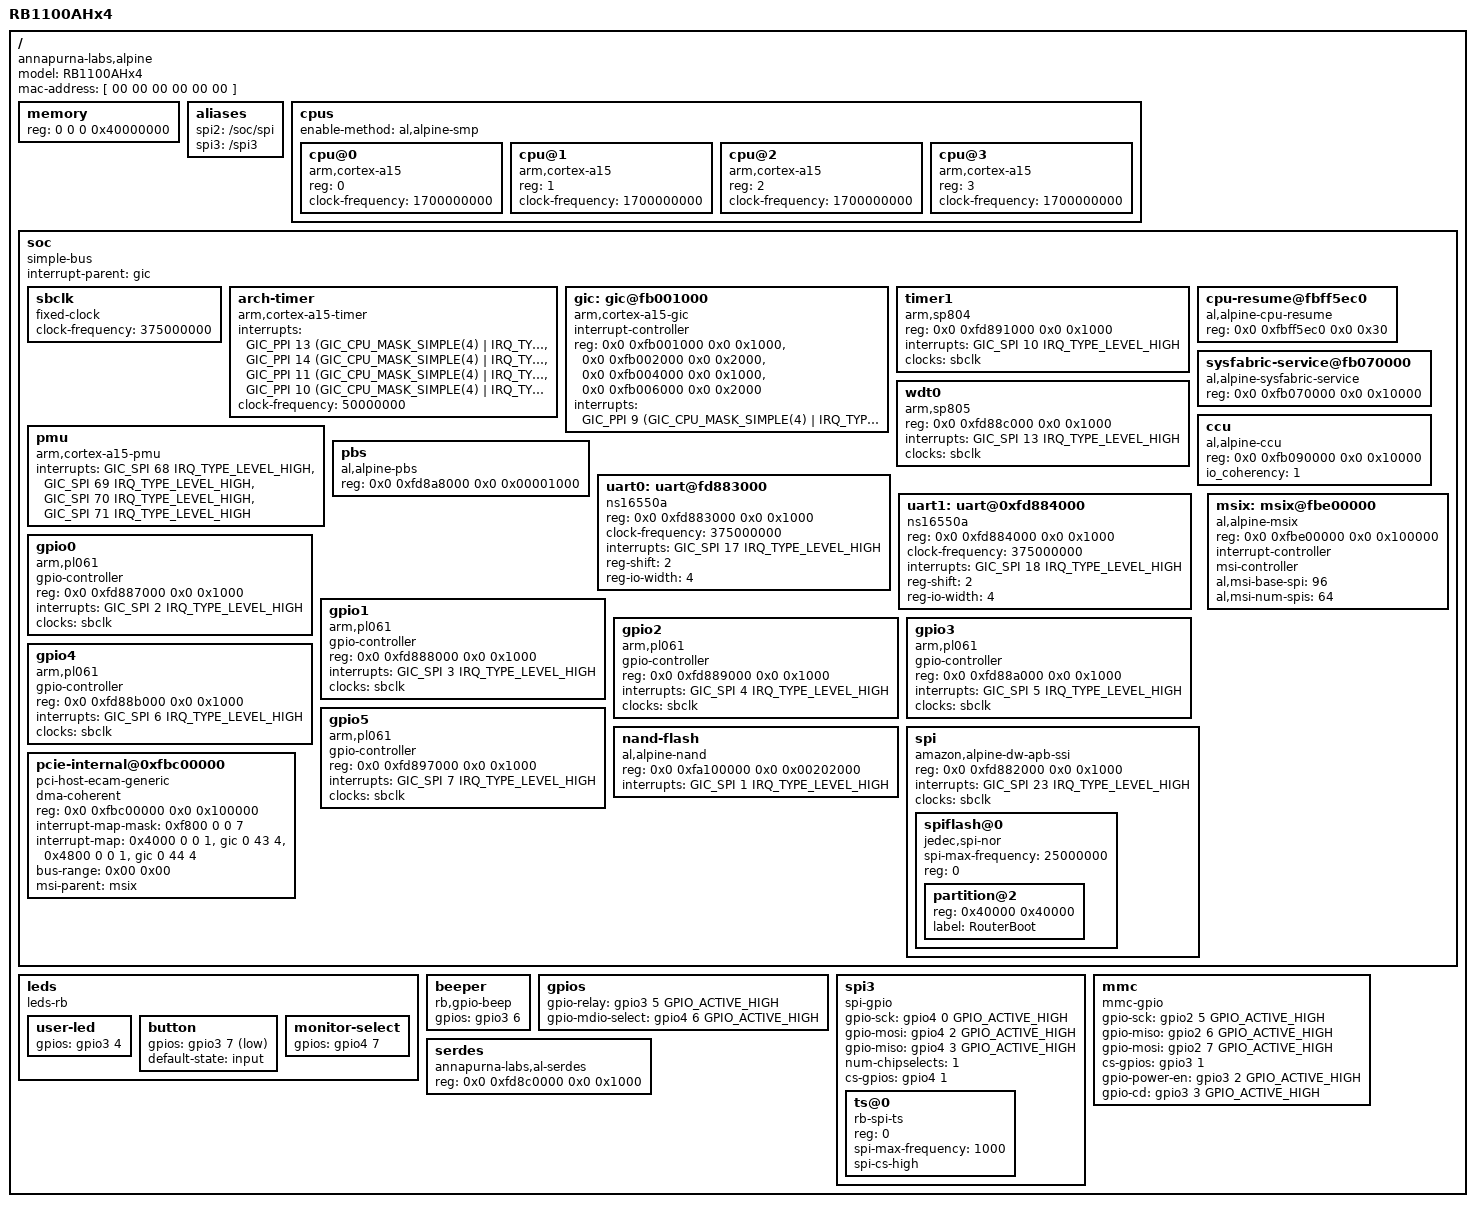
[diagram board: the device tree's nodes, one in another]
/dts-v1/;

#include <dt-bindings/interrupt-controller/arm-gic.h>
#include <dt-bindings/gpio/gpio.h>

/ {
	#address-cells = <2>;
	#size-cells = <2>;
	model = "RB1100AHx4";
	
	/* SOC compatibility */
	compatible = "annapurna-labs,alpine";

	mac-address = [ 00 00 00 00 00 00 ];
	
	memory {
	       device_type = "memory";
	       reg = <0 0 0 0x40000000>;
	};

	aliases {
		spi2 = "/soc/spi";
		spi3 = "/spi3";
	};
	
	/* CPU Configuration */
	cpus {
		#address-cells = <1>;
		#size-cells = <0>;
		enable-method = "al,alpine-smp";

		cpu@0 {
			compatible = "arm,cortex-a15";
			device_type = "cpu";
			reg = <0>;
			clock-frequency = <1700000000>;
		};

		cpu@1 {
			compatible = "arm,cortex-a15";
			device_type = "cpu";
			reg = <1>;
			clock-frequency = <1700000000>;
		};

		cpu@2 {
			compatible = "arm,cortex-a15";
			device_type = "cpu";
			reg = <2>;
			clock-frequency = <1700000000>;
		};

		cpu@3 {
			compatible = "arm,cortex-a15";
			device_type = "cpu";
			reg = <3>;
			clock-frequency = <1700000000>;
		};
	};

	soc {
		#address-cells = <2>;
		#size-cells = <2>;
		compatible = "simple-bus";
		interrupt-parent = <&gic>;
		ranges;

		sbclk: sbclk {
			#address-cells = <1>;
			#size-cells = <0>;
			#clock-cells = <0>;
			compatible = "fixed-clock";
			clock-frequency = <375000000>;
		};

		arch-timer {
			compatible = "arm,cortex-a15-timer",
				     "arm,armv7-timer";
			interrupts =
				<GIC_PPI 13 (GIC_CPU_MASK_SIMPLE(4) | IRQ_TYPE_LEVEL_LOW)>,
				<GIC_PPI 14 (GIC_CPU_MASK_SIMPLE(4) | IRQ_TYPE_LEVEL_LOW)>,
				<GIC_PPI 11 (GIC_CPU_MASK_SIMPLE(4) | IRQ_TYPE_LEVEL_LOW)>,
				<GIC_PPI 10 (GIC_CPU_MASK_SIMPLE(4) | IRQ_TYPE_LEVEL_LOW)>;
			clock-frequency = <50000000>;
		};

		/* Interrupt Controller */
		gic: gic@fb001000 {
			compatible = "arm,cortex-a15-gic";
			#interrupt-cells = <3>;
			#size-cells = <0>;
			#address-cells = <0>;
			interrupt-controller;
			reg = <0x0 0xfb001000 0x0 0x1000>,
			      <0x0 0xfb002000 0x0 0x2000>,
			      <0x0 0xfb004000 0x0 0x1000>,
			      <0x0 0xfb006000 0x0 0x2000>;
			interrupts =
				<GIC_PPI 9 (GIC_CPU_MASK_SIMPLE(4) | IRQ_TYPE_LEVEL_HIGH)>;
		};

		timer1 {
			compatible = "arm,sp804", "arm,primecell";
			reg = <0x0 0xfd891000 0x0 0x1000>;
			interrupts = <GIC_SPI 10 IRQ_TYPE_LEVEL_HIGH>;
			clocks = <&sbclk>;
			clock-names = "apb_pclk";
		};
		
		wdt0 {
			compatible = "arm,sp805", "arm,primecell";
			reg = <0x0 0xfd88c000 0x0 0x1000>;
			interrupts = <GIC_SPI 13 IRQ_TYPE_LEVEL_HIGH>;
			clocks = <&sbclk>;
			clock-names = "apb_pclk";
		};
		
		/* CPU Resume registers */
		cpu-resume@fbff5ec0 {
			compatible = "al,alpine-cpu-resume";
			reg = <0x0 0xfbff5ec0 0x0 0x30>;
		};

		/* North Bridge Service Registers */
		sysfabric-service@fb070000 {
			compatible = "al,alpine-sysfabric-service", "syscon";
			reg = <0x0 0xfb070000 0x0 0x10000>;
		};

		ccu {
			compatible = "al,alpine-ccu";
			reg = <0x0 0xfb090000 0x0 0x10000>;
			io_coherency = <1>;
		};
		
		/* Performance Monitor Unit */
		pmu {
			compatible = "arm,cortex-a15-pmu";
			interrupts = <GIC_SPI 68 IRQ_TYPE_LEVEL_HIGH>,
				     <GIC_SPI 69 IRQ_TYPE_LEVEL_HIGH>,
				     <GIC_SPI 70 IRQ_TYPE_LEVEL_HIGH>,
				     <GIC_SPI 71 IRQ_TYPE_LEVEL_HIGH>;
		};
		
		pbs {
			compatible = "al,alpine-pbs";
			reg = <0x0 0xfd8a8000 0x0 0x00001000>;
		};

		uart0:uart@fd883000 {
			compatible = "ns16550a";
			reg = <0x0 0xfd883000 0x0 0x1000>;
			clock-frequency = <375000000>;
			interrupts = <GIC_SPI 17 IRQ_TYPE_LEVEL_HIGH>;
			reg-shift = <2>;
			reg-io-width = <4>;
		};

		uart1:uart@0xfd884000 {
			compatible = "ns16550a";
			reg = <0x0 0xfd884000 0x0 0x1000>;
			clock-frequency = <375000000>;
			interrupts = <GIC_SPI 18 IRQ_TYPE_LEVEL_HIGH>;
			reg-shift = <2>;
			reg-io-width = <4>;
		};

		gpio0: gpio0 {
			#gpio-cells = <2>;
			compatible = "arm,pl061", "arm,primecell";
			gpio-controller;
			reg = <0x0 0xfd887000 0x0 0x1000>;
			interrupts = <GIC_SPI 2 IRQ_TYPE_LEVEL_HIGH>;
			clocks = <&sbclk>;
			clock-names = "apb_pclk";
		};

		gpio1: gpio1 {
			#gpio-cells = <2>;
			compatible = "arm,pl061", "arm,primecell";
			gpio-controller;
			reg = <0x0 0xfd888000 0x0 0x1000>;
			interrupts = <GIC_SPI 3 IRQ_TYPE_LEVEL_HIGH>;
			clocks = <&sbclk>;
			clock-names = "apb_pclk";
		};

		gpio2: gpio2 {
			#gpio-cells = <2>;
			compatible = "arm,pl061", "arm,primecell";
			gpio-controller;
			reg = <0x0 0xfd889000 0x0 0x1000>;
			interrupts = <GIC_SPI 4 IRQ_TYPE_LEVEL_HIGH>;
			clocks = <&sbclk>;
			clock-names = "apb_pclk";
		};

		gpio3: gpio3 {
			#gpio-cells = <2>;
			compatible = "arm,pl061", "arm,primecell";
			gpio-controller;
			reg = <0x0 0xfd88a000 0x0 0x1000>;
			interrupts = <GIC_SPI 5 IRQ_TYPE_LEVEL_HIGH>;
			clocks = <&sbclk>;
			clock-names = "apb_pclk";
		};

		gpio4: gpio4 {
			#gpio-cells = <2>;
			compatible = "arm,pl061", "arm,primecell";
			gpio-controller;
			reg = <0x0 0xfd88b000 0x0 0x1000>;
			interrupts = <GIC_SPI 6 IRQ_TYPE_LEVEL_HIGH>;
			clocks = <&sbclk>;
			clock-names = "apb_pclk";
		};

		gpio5: gpio5 {
			#gpio-cells = <2>;
			compatible = "arm,pl061", "arm,primecell";
			gpio-controller;
			reg = <0x0 0xfd897000 0x0 0x1000>;
			interrupts = <GIC_SPI 7 IRQ_TYPE_LEVEL_HIGH>;
			clocks = <&sbclk>;
			clock-names = "apb_pclk";
		};
		
		nand-flash {
			compatible = "al,alpine-nand";
			reg = <0x0 0xfa100000 0x0 0x00202000>;
			interrupts = <GIC_SPI 1 IRQ_TYPE_LEVEL_HIGH>;
		};

		spi {
			compatible = "amazon,alpine-dw-apb-ssi";
			#address-cells = <1>;
			#size-cells = <0>;
			reg = <0x0 0xfd882000 0x0 0x1000>;
			interrupts = <GIC_SPI 23 IRQ_TYPE_LEVEL_HIGH>;
			clocks = <&sbclk>;

			spiflash@0 {
				#address-cells = <1>;
				#size-cells = <1>;
				compatible = "jedec,spi-nor";
				spi-max-frequency = <25000000>; /* 25MHz */
				reg = <0>;

				partition@2 {
					reg = <0x40000 0x40000>;
					label = "RouterBoot";
				};
			};
		};

		/* Internal PCIe Controller */
		pcie-internal@0xfbc00000 {
			compatible = "pci-host-ecam-generic";
			device_type = "pci";
			dma-coherent;
			#size-cells = <2>;
			#address-cells = <3>;
			#interrupt-cells = <1>;
			reg = <0x0 0xfbc00000 0x0 0x100000>;
			interrupt-map-mask = <0xf800 0 0 7>;
			interrupt-map =	<0x4000 0 0 1 &gic 0 43 4>,
					<0x4800 0 0 1 &gic 0 44 4>;

			/* 32 bit non prefetchable memory space */
			ranges = <0x02000000 0x0 0xfe000000 0x0 0xfe000000 0x0 0x1000000>;

			bus-range = <0x00 0x00>;
			msi-parent = <&msix>;
		};

		msix: msix@fbe00000 {
			compatible = "al,alpine-msix";
			reg = <0x0 0xfbe00000 0x0 0x100000>;
			interrupt-controller;
			msi-controller;
			al,msi-base-spi = <96>;
			al,msi-num-spis = <64>;
		};
	};

	leds {
		compatible = "leds-rb";
		user-led {
			gpios = <&gpio3 4 GPIO_ACTIVE_HIGH>;
		};
		button {
			gpios = <&gpio3 7 GPIO_ACTIVE_LOW>;
			default-state = "input";
		};
		monitor-select {
			gpios = <&gpio4 7 GPIO_ACTIVE_HIGH>;
		};
	};
	
	beeper {
	        compatible = "rb,gpio-beep";
		gpios = <&gpio3 6 GPIO_ACTIVE_HIGH>;
	};

	gpios {
	        gpio-relay = <&gpio3 5 GPIO_ACTIVE_HIGH>;
	        gpio-mdio-select = <&gpio4 6 GPIO_ACTIVE_HIGH>;
	};

	spi3 {
	        compatible = "spi-gpio";
		#address-cells = <1>;
		#size-cells = <0>;
		
		gpio-sck = <&gpio4 0 GPIO_ACTIVE_HIGH>;
		gpio-mosi = <&gpio4 2 GPIO_ACTIVE_HIGH>;
		gpio-miso = <&gpio4 3 GPIO_ACTIVE_HIGH>;
		num-chipselects = <1>;
		cs-gpios = <&gpio4 1 GPIO_ACTIVE_HIGH>;

		ts@0 {
			compatible = "rb-spi-ts";
			reg = <0>;
			spi-max-frequency = <1000>;
			spi-cs-high;
		};
	};

	mmc {
		compatible = "mmc-gpio";
		gpio-sck = <&gpio2 5 GPIO_ACTIVE_HIGH>;
		gpio-miso = <&gpio2 6 GPIO_ACTIVE_HIGH>;
		gpio-mosi = <&gpio2 7 GPIO_ACTIVE_HIGH>;
		cs-gpios = <&gpio3 1 GPIO_ACTIVE_HIGH>;
		gpio-power-en = <&gpio3 2 GPIO_ACTIVE_HIGH>;
		gpio-cd = <&gpio3 3 GPIO_ACTIVE_HIGH>;
	};
	serdes {
	       compatible = "annapurna-labs,al-serdes";
	       reg = <0x0 0xfd8c0000 0x0 0x1000>;
	};
};
